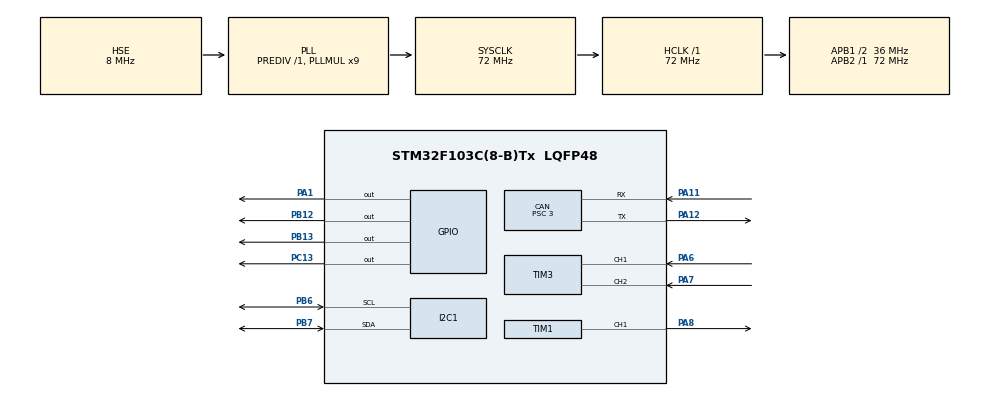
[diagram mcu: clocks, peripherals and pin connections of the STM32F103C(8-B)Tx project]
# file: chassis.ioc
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CAN.ABOM=ENABLE
CAN.BS1=CAN_BS1_9TQ
CAN.BS2=CAN_BS2_2TQ
CAN.CalculateBaudRate=999999
CAN.CalculateTimeBit=1000
CAN.CalculateTimeQuantum=83.33333333333334
CAN.Mode=CAN_MODE_NORMAL
CAN.Prescaler=3
FREERTOS.Tasks01=motor_task,2,256,StartMotorTask,Default,NULL,Dynamic,NULL,NULL;can_send_task,0,128,StartCanSendTask,Default,NULL,Dynamic,NULL,NULL;health_task,-2,128,StartHealthTask,Default,NULL,Dynamic,NULL,NULL;led_task,-2,128,StartLedTask,Default,NULL,Dynamic,NULL,NULL;display_task,-2,256,StartDisplayTask,Default,NULL,Dynamic,NULL,NULL
FREERTOS.configTOTAL_HEAP_SIZE=8192
I2C1.I2C_Mode=I2C_Standard
Mcu.Family=STM32F1
Mcu.Name=STM32F103C(8-B)Tx
Mcu.Package=LQFP48
NVIC.PriorityGroup=NVIC_PRIORITYGROUP_4
NVIC.TIM2_IRQn=true\:5\:0\:false\:false\:true\:true\:true\:true\:true
NVIC.TIM4_IRQn=true\:15\:0\:false\:false\:true\:false\:false\:true\:true
NVIC.TimeBase=TIM4_IRQn
NVIC.TimeBaseIP=TIM4
NVIC.USB_LP_CAN1_RX0_IRQn=true\:5\:0\:false\:false\:true\:true\:true\:true\:true
PA1.PinState=GPIO_PIN_SET
PA1.Signal=GPIO_Output
PA11.Mode=CAN_Activate
PA11.Signal=CAN_RX
PA12.Mode=CAN_Activate
PA12.Signal=CAN_TX
PA13.Mode=Serial_Wire
PA13.Signal=SYS_JTMS-SWDIO
PA14.Mode=Serial_Wire
PA14.Signal=SYS_JTCK-SWCLK
PA6.Signal=S_TIM3_CH1
PA7.Signal=S_TIM3_CH2
PA8.Signal=S_TIM1_CH1
PB12.Signal=GPIO_Output
PB13.Signal=GPIO_Output
PB6.Mode=I2C
PB6.Signal=I2C1_SCL
PB7.Mode=I2C
PB7.Signal=I2C1_SDA
PC13-TAMPER-RTC.Signal=GPIO_Output
PD0-OSC_IN.Mode=HSE-External-Oscillator
PD0-OSC_IN.Signal=RCC_OSC_IN
PD1-OSC_OUT.Mode=HSE-External-Oscillator
PD1-OSC_OUT.Signal=RCC_OSC_OUT
ProjectManager.HeapSize=0x200
ProjectManager.StackSize=0x400
ProjectManager.TargetToolchain=CMake
RCC.AHBFreq_Value=72000000
RCC.APB1CLKDivider=RCC_HCLK_DIV2
RCC.APB1Freq_Value=36000000
RCC.APB1TimFreq_Value=72000000
RCC.APB2Freq_Value=72000000
RCC.APB2TimFreq_Value=72000000
RCC.HCLKFreq_Value=72000000
RCC.PLLMUL=RCC_PLL_MUL9
RCC.PLLSourceVirtual=RCC_PLLSOURCE_HSE
RCC.SYSCLKFreq_VALUE=72000000
RCC.SYSCLKSource=RCC_SYSCLKSOURCE_PLLCLK
RCC.USBFreq_Value=72000000
SH.S_TIM1_CH1.0=TIM1_CH1,PWM Generation1 CH1
SH.S_TIM3_CH1.0=TIM3_CH1,Encoder_Interface
SH.S_TIM3_CH2.0=TIM3_CH2,Encoder_Interface
TIM1.Channel-PWM\ Generation1\ CH1=TIM_CHANNEL_1
TIM1.Period=3599
TIM2.Period=999
TIM2.Prescaler=71
TIM3.EncoderMode=TIM_ENCODERMODE_TI12
VP_FREERTOS_VS_CMSIS_V1.Mode=CMSIS_V1
VP_SYS_VS_tim4.Mode=TIM4
VP_TIM2_VS_ClockSourceINT.Mode=Internal
board=custom

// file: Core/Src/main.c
/* USER CODE BEGIN Header */
/**
  ******************************************************************************
  * @file           : main.c
  * @brief          : Main program body
  ******************************************************************************
  * @attention
  *
  * Copyright (c) 2026 STMicroelectronics.
  * All rights reserved.
  *
  * This software is licensed under terms that can be found in the LICENSE file
  * in the root directory of this software component.
  * If no LICENSE file comes with this software, it is provided AS-IS.
  *
  ******************************************************************************
  */
/* USER CODE END Header */
#include "main.h"
#include "cmsis_os.h"
#include "can.h"
#include "i2c.h"
#include "tim.h"
#include "gpio.h"

/* USER CODE BEGIN Includes */
#include "can_bus.h"
/* USER CODE END Includes */

void SystemClock_Config(void);
void MX_FREERTOS_Init(void);

int main(void)
{

  /* MCU Configuration--------------------------------------------------------*/

  /* Reset of all peripherals, Initializes the Flash interface and the Systick. */
  HAL_Init();

  /* Configure the system clock */
  SystemClock_Config();

  /* Initialize all configured peripherals */
  MX_GPIO_Init();
  MX_CAN_Init();
  MX_TIM3_Init();
  MX_I2C1_Init();
  MX_TIM1_Init();
  MX_TIM2_Init();
  /* USER CODE BEGIN 2 */
  can_bus_init();//can通信发送函数初始化
  /* USER CODE END 2 */

  /* Call init function for freertos objects (in cmsis_os2.c) */
  MX_FREERTOS_Init();

  /* Start scheduler */
  osKernelStart();

  /* We should never get here as control is now taken by the scheduler */

  /* Infinite loop */
  while (1)
  {

  }
}

void SystemClock_Config(void)
{
  RCC_OscInitTypeDef RCC_OscInitStruct = {0};
  RCC_ClkInitTypeDef RCC_ClkInitStruct = {0};

  /** Initializes the RCC Oscillators according to the specified parameters
  * in the RCC_OscInitTypeDef structure.
  */
  RCC_OscInitStruct.OscillatorType = RCC_OSCILLATORTYPE_HSE;
  RCC_OscInitStruct.HSEState = RCC_HSE_ON;
  RCC_OscInitStruct.HSEPredivValue = RCC_HSE_PREDIV_DIV1;
  RCC_OscInitStruct.HSIState = RCC_HSI_ON;
  RCC_OscInitStruct.PLL.PLLState = RCC_PLL_ON;
  RCC_OscInitStruct.PLL.PLLSource = RCC_PLLSOURCE_HSE;
  RCC_OscInitStruct.PLL.PLLMUL = RCC_PLL_MUL9;
  if (HAL_RCC_OscConfig(&RCC_OscInitStruct) != HAL_OK)
  {
    Error_Handler();
  }

  /** Initializes the CPU, AHB and APB buses clocks
  */
  RCC_ClkInitStruct.ClockType = RCC_CLOCKTYPE_HCLK|RCC_CLOCKTYPE_SYSCLK
                              |RCC_CLOCKTYPE_PCLK1|RCC_CLOCKTYPE_PCLK2;
  RCC_ClkInitStruct.SYSCLKSource = RCC_SYSCLKSOURCE_PLLCLK;
  RCC_ClkInitStruct.AHBCLKDivider = RCC_SYSCLK_DIV1;
  RCC_ClkInitStruct.APB1CLKDivider = RCC_HCLK_DIV2;
  RCC_ClkInitStruct.APB2CLKDivider = RCC_HCLK_DIV1;

  if (HAL_RCC_ClockConfig(&RCC_ClkInitStruct, FLASH_LATENCY_2) != HAL_OK)
  {
    Error_Handler();
  }
}

void HAL_TIM_PeriodElapsedCallback(TIM_HandleTypeDef *htim)
{
  if (htim->Instance == TIM4)
  {
    HAL_IncTick();
  }
}

void Error_Handler(void)
{
  __disable_irq();
  while (1)
  {
  }
}

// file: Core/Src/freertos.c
/* USER CODE BEGIN Header */
/**
  ******************************************************************************
  * File Name          : freertos.c
  * Description        : Code for freertos applications
  ******************************************************************************
  * @attention
  *
  * Copyright (c) 2026 STMicroelectronics.
  * All rights reserved.
  *
  * This software is licensed under terms that can be found in the LICENSE file
  * in the root directory of this software component.
  * If no LICENSE file comes with this software, it is provided AS-IS.
  *
  ******************************************************************************
  */
/* USER CODE END Header */

#include "FreeRTOS.h"
#include "task.h"
#include "main.h"
#include "cmsis_os.h"

osThreadId motor_taskHandle;
osThreadId can_send_taskHandle;
osThreadId health_taskHandle;
osThreadId led_taskHandle;
osThreadId display_taskHandle;

void StartMotorTask(void const * argument);
void StartCanSendTask(void const * argument);
void StartHealthTask(void const * argument);
void StartLedTask(void const * argument);
void StartDisplayTask(void const * argument);

void MX_FREERTOS_Init(void); /* (MISRA C 2004 rule 8.1) */

/* GetIdleTaskMemory prototype (linked to static allocation support) */
void vApplicationGetIdleTaskMemory( StaticTask_t **ppxIdleTaskTCBBuffer, StackType_t **ppxIdleTaskStackBuffer, uint32_t *pulIdleTaskStackSize );

/* USER CODE BEGIN GET_IDLE_TASK_MEMORY */
static StaticTask_t xIdleTaskTCBBuffer;
static StackType_t xIdleStack[configMINIMAL_STACK_SIZE];

void vApplicationGetIdleTaskMemory( StaticTask_t **ppxIdleTaskTCBBuffer, StackType_t **ppxIdleTaskStackBuffer, uint32_t *pulIdleTaskStackSize )
{
  *ppxIdleTaskTCBBuffer = &xIdleTaskTCBBuffer;
  *ppxIdleTaskStackBuffer = &xIdleStack[0];
  *pulIdleTaskStackSize = configMINIMAL_STACK_SIZE;
  /* place for user code */
}
/* USER CODE END GET_IDLE_TASK_MEMORY */

void MX_FREERTOS_Init(void) {

  /* Create the thread(s) */
  /* definition and creation of motor_task */
  osThreadDef(motor_task, StartMotorTask, osPriorityHigh, 0, 256);
  motor_taskHandle = osThreadCreate(osThread(motor_task), NULL);

  /* definition and creation of can_send_task */
  osThreadDef(can_send_task, StartCanSendTask, osPriorityNormal, 0, 128);
  can_send_taskHandle = osThreadCreate(osThread(can_send_task), NULL);

  /* definition and creation of health_task */
  osThreadDef(health_task, StartHealthTask, osPriorityLow, 0, 128);
  health_taskHandle = osThreadCreate(osThread(health_task), NULL);

  /* definition and creation of led_task */
  osThreadDef(led_task, StartLedTask, osPriorityLow, 0, 128);
  led_taskHandle = osThreadCreate(osThread(led_task), NULL);

  /* definition and creation of display_task */
  osThreadDef(display_task, StartDisplayTask, osPriorityLow, 0, 256);
  display_taskHandle = osThreadCreate(osThread(display_task), NULL);

}

__weak void StartMotorTask(void const * argument)
{
  /* USER CODE BEGIN StartMotorTask */
  /* Infinite loop */
  for(;;)
  {
    osDelay(10);
  }
  /* USER CODE END StartMotorTask */
}

__weak void StartCanSendTask(void const * argument)
{
  /* USER CODE BEGIN StartCanSendTask */
  /* Infinite loop */
  for(;;)
  {
    osDelay(10);
  }
  /* USER CODE END StartCanSendTask */
}

__weak void StartHealthTask(void const * argument)
{
  /* USER CODE BEGIN StartHealthTask */
  /* Infinite loop */
  for(;;)
  {
    osDelay(20);
  }
  /* USER CODE END StartHealthTask */
}

__weak void StartLedTask(void const * argument)
{
  for(;;)
  {
    osDelay(1);
  }
}

__weak void StartDisplayTask(void const * argument)
{
  /* USER CODE BEGIN StartDisplayTask */
  /* Infinite loop */
  for(;;)
  {
    osDelay(100);
  }
  /* USER CODE END StartDisplayTask */
}
